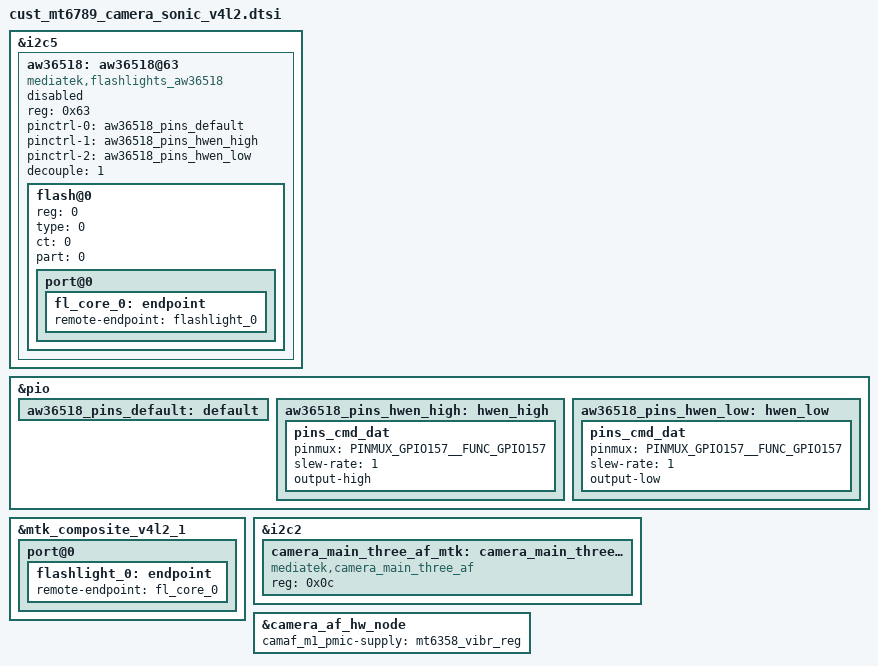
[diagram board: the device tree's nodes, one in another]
// SPDX-License-Identifier: GPL-2.0
/* Copyright (c) 2020 MediaTek Inc. */

&i2c5 {
    aw36518:aw36518@63 {
        compatible = "mediatek,flashlights_aw36518";
        reg = <0x63>;
        #cooling-cells = <2>;
        pinctrl-names = "default", "hwen_high", "hwen_low";
        pinctrl-0 = <&aw36518_pins_default>;
        pinctrl-1 = <&aw36518_pins_hwen_high>;
        pinctrl-2 = <&aw36518_pins_hwen_low>;
        status = "disabled";
        decouple = <1>;
        flash@0{
            reg = <0>;
            type = <0>;
            ct = <0>;
            part = <0>;
            port@0 {
                fl_core_0: endpoint {
                    remote-endpoint = <&flashlight_0>;
                };
            };
        };
    };
};
&pio {
    aw36518_pins_default: default {
    };

    aw36518_pins_hwen_high: hwen_high {
        pins_cmd_dat {
            pinmux = <PINMUX_GPIO157__FUNC_GPIO157>;
            slew-rate = <1>;
            output-high;
        };
    };

    aw36518_pins_hwen_low: hwen_low {
        pins_cmd_dat {
            pinmux = <PINMUX_GPIO157__FUNC_GPIO157>;
            slew-rate = <1>;
            output-low;
        };
    };
};


&mtk_composite_v4l2_1 {
    port@0 {
        flashlight_0: endpoint {
            remote-endpoint = <&fl_core_0>;
        };
    };
};

/* CAMERA AF */
&i2c2 {
    camera_main_three_af_mtk:camera_main_three_af@0c {
        compatible = "mediatek,camera_main_three_af";
        reg = <0x0c>;
        status = "okay";
    };
};

&camera_af_hw_node {
    camaf_m1_pmic-supply = <&mt6358_vibr_reg>;
    //camaf_m3_pmic-supply = <&rt5133_gpio1>;
    status = "okay";
};
/* CAMERA AF end */
